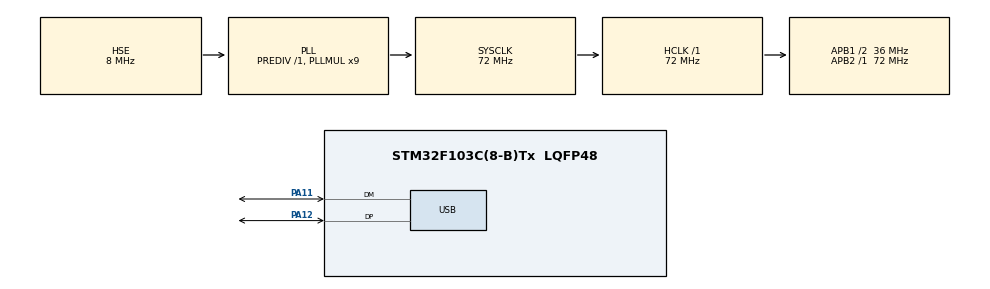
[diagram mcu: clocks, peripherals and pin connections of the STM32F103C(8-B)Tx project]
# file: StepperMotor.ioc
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Mcu.Family=STM32F1
Mcu.Name=STM32F103C(8-B)Tx
Mcu.Package=LQFP48
NVIC.PriorityGroup=NVIC_PRIORITYGROUP_4
NVIC.USB_LP_CAN1_RX0_IRQn=true\:0\:0\:false\:false\:true\:false\:true
PA11.Mode=Device
PA11.Signal=USB_DM
PA12.Mode=Device
PA12.Signal=USB_DP
PA13.Mode=Serial_Wire
PA13.Signal=SYS_JTMS-SWDIO
PA14.Mode=Serial_Wire
PA14.Signal=SYS_JTCK-SWCLK
PD0-OSC_IN.Mode=HSE-External-Oscillator
PD0-OSC_IN.Signal=RCC_OSC_IN
PD1-OSC_OUT.Mode=HSE-External-Oscillator
PD1-OSC_OUT.Signal=RCC_OSC_OUT
ProjectManager.HeapSize=0x400
ProjectManager.StackSize=0x400
ProjectManager.TargetToolchain=MDK-ARM V5
RCC.AHBFreq_Value=72000000
RCC.APB1CLKDivider=RCC_HCLK_DIV2
RCC.APB1Freq_Value=36000000
RCC.APB1TimFreq_Value=72000000
RCC.APB2Freq_Value=72000000
RCC.APB2TimFreq_Value=72000000
RCC.HCLKFreq_Value=72000000
RCC.PLLMUL=RCC_PLL_MUL9
RCC.PLLSourceVirtual=RCC_PLLSOURCE_HSE
RCC.SYSCLKFreq_VALUE=72000000
RCC.SYSCLKSource=RCC_SYSCLKSOURCE_PLLCLK
RCC.USBFreq_Value=48000000
RCC.USBPrescaler=RCC_USBCLKSOURCE_PLL_DIV1_5
USB_DEVICE.CLASS_NAME_FS=CDC
USB_DEVICE.VirtualMode=Cdc
USB_DEVICE.VirtualModeFS=Cdc_FS
VP_USB_DEVICE_VS_USB_DEVICE_CDC_FS.Mode=CDC_FS
board=custom

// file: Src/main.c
/* USER CODE BEGIN Header */
/**
  ******************************************************************************
  * @file           : main.c
  * @brief          : Main program body
  ******************************************************************************
  * @attention
  *
  * <h2><center>&copy; Copyright (c) 2019 STMicroelectronics.
  * All rights reserved.</center></h2>
  *
  * This software component is licensed by ST under BSD 3-Clause license,
  * the "License"; You may not use this file except in compliance with the
  * License. You may obtain a copy of the License at:
  *                        opensource.org/licenses/BSD-3-Clause
  *
  ******************************************************************************
  */
/* USER CODE END Header */

#include "main.h"
#include "usb_device.h"
/* USER CODE BEGIN Includes */
#include "SM_Control.h"
/* USER CODE END Includes */

void SystemClock_Config(void);
static void MX_GPIO_Init(void);
/* USER CODE BEGIN PFP */
void DRC(void);
void APF(void);
void ASV(void);
void Aswitch(char*,int8_t*);
void PRS(void);
int16_t ReadNum(char*,int8_t*);
int16_t ReadNum0(char*);
/* USER CODE END PFP */

int main(void)
{

  /* MCU Configuration--------------------------------------------------------*/

  /* Reset of all peripherals, Initializes the Flash interface and the Systick. */
  HAL_Init();

  /* Configure the system clock */
  SystemClock_Config();

  /* Initialize all configured peripherals */
  MX_GPIO_Init();
  MX_USB_DEVICE_Init();

  /* Infinite loop */
  /* USER CODE BEGIN WHILE */
  while(1)
  {

    Write("To start, print one from the following commands:\n\r1) DRC for direct control\n\r2) APF for performing algorithm\n\r");
    //Write("3) ASV for saving algorithm in memory\n4) PRS for performing algorithm in memory\n");
    HAL_Delay(2000);

    //COM("APF");

    if(strncmp((char*)UserRxBufferFS,"DRC",3)==0)
    {
        Debug("DRCbegin\n\r");

        UserRxBufferFS[0]=(uint8_t)'\0';
        DRC();

        Debug("DRCend\n\r");
    }
    else if(strncmp((char*)UserRxBufferFS,"APF",3)==0)
    {
        Debug("APFbegin\n\r");

        UserRxBufferFS[0]=(uint8_t)'\0';
        APF();

        Debug("APFend\n\r");
    }
    /*
    else if(strncmp((char*)UserRxBufferFS,"ASV",3)==0)
    {
        UserRxBufferFS[0]=(uint8_t)'\0';
        ASV();
    }
    else if(strncmp((char*)UserRxBufferFS,"PRS",3)==0)
    {
        UserRxBufferFS[0]=(uint8_t)'\0';
        PRS();
    }
    */
    /* USER CODE END WHILE */

  }
}

void SystemClock_Config(void)
{
  RCC_OscInitTypeDef RCC_OscInitStruct = {0};
  RCC_ClkInitTypeDef RCC_ClkInitStruct = {0};
  RCC_PeriphCLKInitTypeDef PeriphClkInit = {0};

  /** Initializes the CPU, AHB and APB busses clocks
  */
  RCC_OscInitStruct.OscillatorType = RCC_OSCILLATORTYPE_HSE;
  RCC_OscInitStruct.HSEState = RCC_HSE_ON;
  RCC_OscInitStruct.HSEPredivValue = RCC_HSE_PREDIV_DIV1;
  RCC_OscInitStruct.HSIState = RCC_HSI_ON;
  RCC_OscInitStruct.PLL.PLLState = RCC_PLL_ON;
  RCC_OscInitStruct.PLL.PLLSource = RCC_PLLSOURCE_HSE;
  RCC_OscInitStruct.PLL.PLLMUL = RCC_PLL_MUL9;
  if (HAL_RCC_OscConfig(&RCC_OscInitStruct) != HAL_OK)
  {
    Error_Handler();
  }
  /** Initializes the CPU, AHB and APB busses clocks
  */
  RCC_ClkInitStruct.ClockType = RCC_CLOCKTYPE_HCLK|RCC_CLOCKTYPE_SYSCLK
                              |RCC_CLOCKTYPE_PCLK1|RCC_CLOCKTYPE_PCLK2;
  RCC_ClkInitStruct.SYSCLKSource = RCC_SYSCLKSOURCE_PLLCLK;
  RCC_ClkInitStruct.AHBCLKDivider = RCC_SYSCLK_DIV1;
  RCC_ClkInitStruct.APB1CLKDivider = RCC_HCLK_DIV2;
  RCC_ClkInitStruct.APB2CLKDivider = RCC_HCLK_DIV1;

  if (HAL_RCC_ClockConfig(&RCC_ClkInitStruct, FLASH_LATENCY_2) != HAL_OK)
  {
    Error_Handler();
  }
  PeriphClkInit.PeriphClockSelection = RCC_PERIPHCLK_USB;
  PeriphClkInit.UsbClockSelection = RCC_USBCLKSOURCE_PLL_DIV1_5;
  if (HAL_RCCEx_PeriphCLKConfig(&PeriphClkInit) != HAL_OK)
  {
    Error_Handler();
  }
}

static void MX_GPIO_Init(void)
{

  /* GPIO Ports Clock Enable */
  __HAL_RCC_GPIOD_CLK_ENABLE();
  __HAL_RCC_GPIOA_CLK_ENABLE();

}

/* USER CODE BEGIN 4 */

void DRC()
{
    char str[1000];
    int8_t k;

    Write("\nInput command:\n");

    while(1)
    {
        HAL_Delay(100);
        //COM("HM");
        if(UserRxBufferFS[0]!=(uint8_t)'\0')
            break;
    }

    while(1)
    {
        strcpy(str,(char*)UserRxBufferFS);
        UserRxBufferFS[0]=(uint8_t)'\0';
        Write(str);
        switch(str[0])
        {
            case 'S':
                switch(str[1])
                {
                    case 'P':
                        SPdc(ReadNum0(str));
                        break;
                }
                break;
            case 'M':
                switch(str[1])
                {
                    case 'V':
                        k=0;
                        if('0'<=str[2+k]&&str[2+k]<='9')
                            k=1;
                        if(k==0)
                        {
                            MVdc();
                            break;
                        }
                        MVXdc(ReadNum0(str));
                        break;
                    case 'H':
                        MHdc();
                        break;
                    case 'L':
                        MLdc();
                        break;
                }
                break;
            case 'H':
                switch(str[1])
                {
                    case 'M':
                        HMdc();
                        break;
                }
                break;
            //For parameter changing, LL-JP functions and WL/WH
            default:
                k=0;
                Aswitch(str,&k);
                break;
        }
    }
}

void APF()
{
    char str[1000];

    Write("\nInput your algorithm:\n");
    while(1)
    {
        //COM("WH");
        HAL_Delay(100);
        if(UserRxBufferFS[0]!=(uint8_t)'\0')
            break;
    }

    strcpy(str,(char*)UserRxBufferFS);
    for(int8_t i=0;i<strlen(str)-1;i+=2)
        Aswitch(str,&i);

}
void ASV()
{
    //SAVING ALGORITHM IN FLASH-MEMORY
}

void PRS()
{
    //READING ALGORITHM FROM FLASH-MEMORY
}

void Aswitch(char* str,int8_t* i)
{
    int8_t k=0,j;
    switch(str[*i])
        {
            case 'D':
                switch(str[*i+1])
                {
                    case 'L':
                        DL();
                        break;
                    case 'R':
                        DR();
                        break;
                }
                break;
            case 'R':
                switch(str[*i+1])
                {
                    case 'S':
                        RS();
                        break;
                }
                break;
           case 'A':
                switch(str[*i+1])
                {
                    case 'L':
                        AL(ReadNum(str,i));
                        break;
                }
                break;
            case 'S':
                switch(str[*i+1])
                {
                    case 'D':
                        SD(ReadNum(str,i));
                        break;
                    case 'S':
                        SS(ReadNum(str,i));
                        break;
                    case 'P':
                        SP(ReadNum(str,i));
                        break;
                }
                break;
            case 'M':
                switch(str[*i+1])
                {
                    case 'V':
                        k=0;
                        if('0'<=str[*i+2+k]&&str[*i+2+k]<='9')
                            k=1;
                        if(k==0)
                        {
                            MV();
                            break;
                        }
                        MVX(ReadNum(str,i));
                        break;
                    case 'H':
                        MH();
                        break;
                    case 'L':
                        ML();
                        break;
                }
                break;
            case 'H':
                switch(str[*i+1])
                {
                    case 'M':
                        HM();
                        break;
                }
                break;
            case 'L':
                switch(str[*i+1])
                {
                    case 'L':
                        j=*i+2;
                        while(!(str[j]=='J'&&str[j+1]=='P'))
                            j+=2;
                        int8_t temp=j;
                        temp=ReadNum(str,&temp);
                        for(int8_t t=0;t<temp;t++)
                            for(int8_t p=*i+2;p<j;p+=2)
                                Aswitch(str,&p);
                        break;
                }
                break;
            case 'W':
                switch(str[*i+1])
                {
                    case 'L':
                        WL();
                        break;
                    case 'H':
                        WH();
                        break;
                }
        }
}

extern void NoInterrupt(){
    char str[64];
    strncpy(str,(char*)UserRxBufferFS,64);

     switch(str[0])
        {
            case 'S':
                switch(str[1])
                {
                    case 'P':
                        SPdc(ReadNum(str,0));
                        break;
                }
                break;
            //For parameter changing functions
            default:
                Aswitch(str,0);
            break;
        }
}

int16_t ReadNum(char* str,int8_t* i){
    int8_t k=0;
    char temp[10];
    while(('0'<=str[*i+2+k]&&str[*i+2+k]<='9')||str[*i+2+k]=='-'||str[*i+2+k]=='+')
        k++;
    for(int8_t j=0;j<k;j++)
        temp[j]=str[*i+2+j];
    *i+=k;
    return atoi(temp);
}

int16_t ReadNum0(char* str){
    int8_t k=0;
    char temp[10];
    while(('0'<=str[2+k]&&str[2+k]<='9')||str[2+k]=='-'||str[2+k]=='+')
        k++;
    for(int8_t j=0;j<k;j++)
        temp[j]=str[2+j];
    return atoi(temp);
}
/* USER CODE END 4 */

void Error_Handler(void)
{
}

/************************ (C) COPYRIGHT STMicroelectronics *****END OF FILE****/
